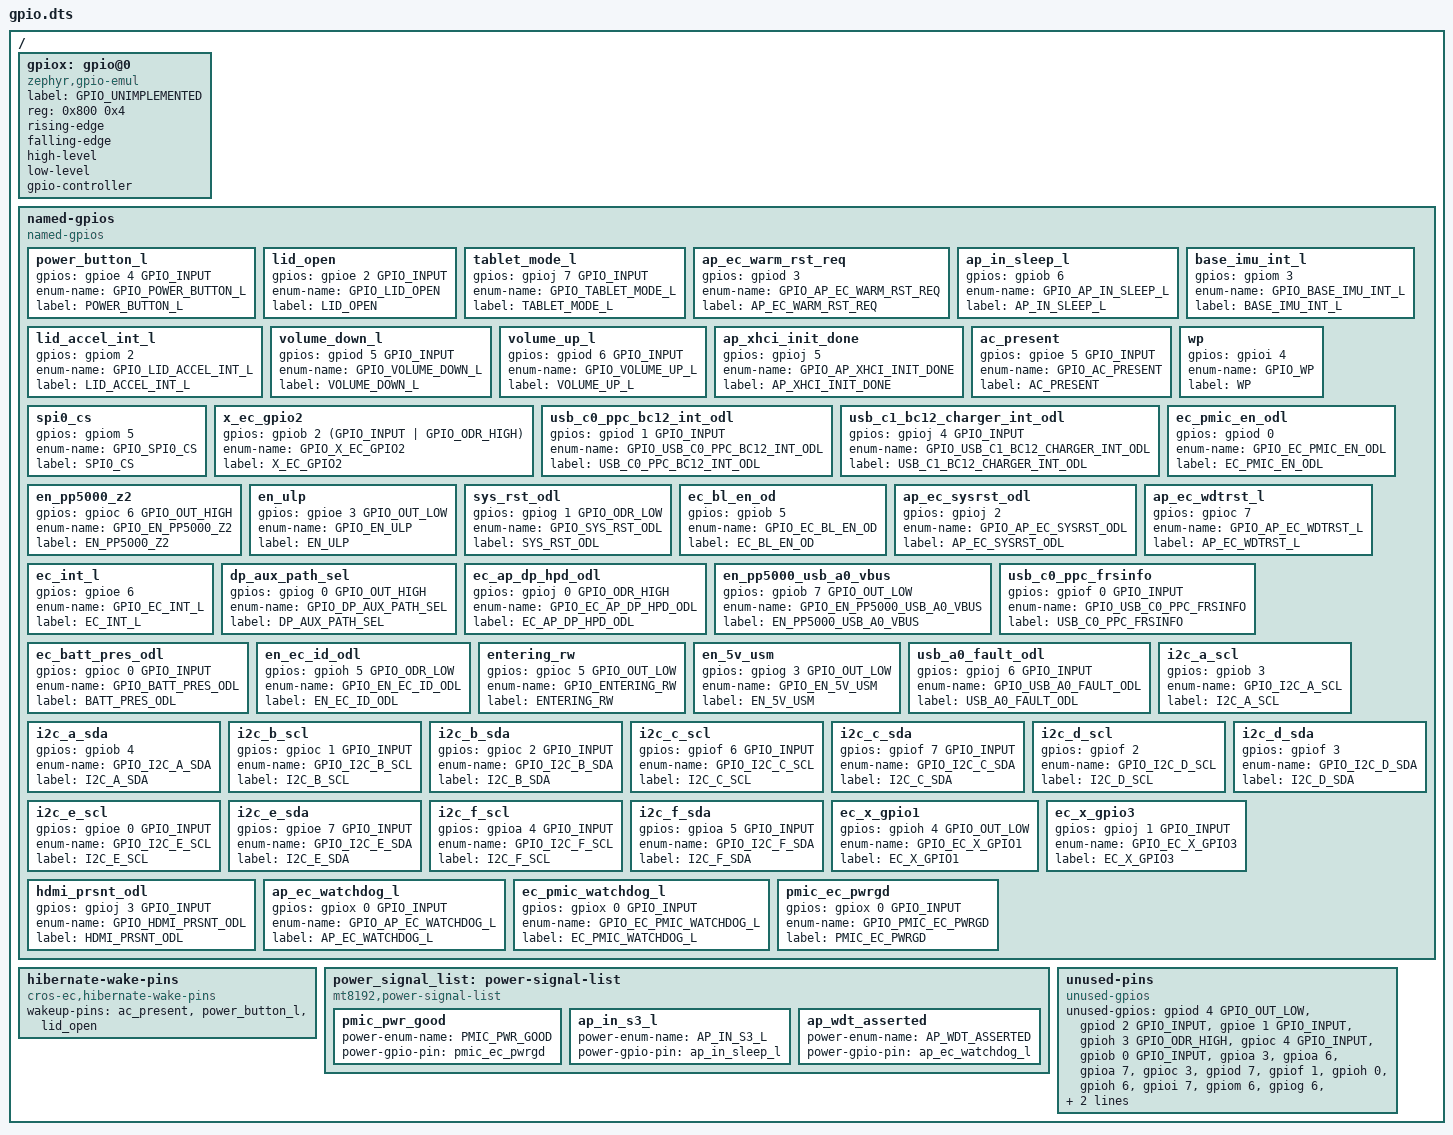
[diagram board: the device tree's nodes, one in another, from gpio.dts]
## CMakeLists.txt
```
# Copyright 2021 The Chromium OS Authors. All rights reserved.
# Use of this source code is governed by a BSD-style license that can be
# found in the LICENSE file.

cmake_minimum_required(VERSION 3.13.1)
add_compile_definitions(BOARD_KRABBY)

find_package(Zephyr REQUIRED HINTS $ENV{ZEPHYR_BASE})
project(krabby)

zephyr_library_include_directories(include)

set(PLATFORM_EC_BASEBOARD "${PLATFORM_EC}/baseboard/corsola" CACHE PATH
    "Path to the platform/ec baseboard directory")
set(PLATFORM_EC_BOARD "${PLATFORM_EC}/board/krabby" CACHE PATH
  "Path to the platform/ec board directory")

# Include selected EC source from the baseboard
zephyr_library_sources(
  "${PLATFORM_EC_BASEBOARD}/board_chipset.c"
  "${PLATFORM_EC_BASEBOARD}/board_id.c"
  "${PLATFORM_EC_BASEBOARD}/hibernate.c"
  "${PLATFORM_EC_BASEBOARD}/regulator.c"
  "${PLATFORM_EC_BASEBOARD}/usbc_config.c"
  "${PLATFORM_EC_BASEBOARD}/usb_pd_policy.c")

# Include selected EC source from the board
zephyr_library_sources(
  "${PLATFORM_EC_BOARD}/hooks.c"
  "${PLATFORM_EC_BOARD}/led.c")

zephyr_library_sources_ifdef(CONFIG_PLATFORM_EC_I2C
  "src/i2c.c")
```

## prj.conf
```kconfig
# Copyright 2021 The Chromium OS Authors. All rights reserved.
# Use of this source code is governed by a BSD-style license that can be
# found in the LICENSE file.

CONFIG_CROS_EC=y
CONFIG_PLATFORM_EC=y
CONFIG_SHIMMED_TASKS=y

# Bring up options
CONFIG_KERNEL_SHELL=y
CONFIG_PLATFORM_EC_SYSTEM_UNLOCKED=y
CONFIG_GPIO_EMUL=y

# Battery
CONFIG_PLATFORM_EC_BATTERY=y
CONFIG_PLATFORM_EC_BATTERY_CUT_OFF=y
CONFIG_PLATFORM_EC_BATTERY_FUEL_GAUGE=y
CONFIG_PLATFORM_EC_BATTERY_PRESENT_GPIO=y
CONFIG_PLATFORM_EC_BATTERY_SMART=y
CONFIG_PLATFORM_EC_BATT_FULL_CHIPSET_OFF_INPUT_LIMIT_MV=9000
CONFIG_PLATFORM_EC_I2C_PASSTHRU_RESTRICTED=y
CONFIG_PLATFORM_EC_I2C_VIRTUAL_BATTERY=y

# Charger
CONFIG_PLATFORM_EC_CHARGE_MANAGER=y
CONFIG_PLATFORM_EC_CHARGE_RAMP_HW=y
CONFIG_PLATFORM_EC_CHARGER_DISCHARGE_ON_AC=y
CONFIG_PLATFORM_EC_CHARGER_DISCHARGE_ON_AC_CHARGER=y
CONFIG_PLATFORM_EC_CHARGER_ISL9238C=y
CONFIG_PLATFORM_EC_CHARGER_MAINTAIN_VBAT=y
CONFIG_PLATFORM_EC_CHARGER_OTG=y
CONFIG_PLATFORM_EC_CHARGER_PSYS=y
CONFIG_PLATFORM_EC_CHARGER_PSYS_READ=y
# BOARD_RS2
CONFIG_PLATFORM_EC_CHARGER_SENSE_RESISTOR=10
# BOARD_RS1
CONFIG_PLATFORM_EC_CHARGER_SENSE_RESISTOR_AC=20

# Host Commands
CONFIG_PLATFORM_EC_HOSTCMD=y
CONFIG_PLATFORM_EC_CONSOLE_CMD_ACCELS=y
CONFIG_PLATFORM_EC_CONSOLE_CMD_ACCEL_INFO=y
CONFIG_PLATFORM_EC_CONSOLE_CMD_CHARGER_ADC_AMON_BMON=y
CONFIG_PLATFORM_EC_CONSOLE_CMD_SYSINFO=y
CONFIG_PLATFORM_EC_HOSTCMD_REGULATOR=y
CONFIG_PLATFORM_EC_HOST_COMMAND_STATUS=y

# LED
CONFIG_PLATFORM_EC_LED_COMMON=y
CONFIG_PLATFORM_EC_LED_ONOFF_STATES=y
CONFIG_PLATFORM_EC_LED_ONOFF_STATES_BAT_LOW=10

# MKBP event mask
CONFIG_PLATFORM_EC_MKBP_EVENT_WAKEUP_MASK=y
CONFIG_PLATFORM_EC_MKBP_HOST_EVENT_WAKEUP_MASK=y
CONFIG_PLATFORM_EC_MKBP_USE_GPIO=y

# Keyboard
CONFIG_PLATFORM_EC_KEYBOARD=y
CONFIG_PLATFORM_EC_KEYBOARD_PROTOCOL_MKBP=y
CONFIG_PLATFORM_EC_KEYBOARD_COL2_INVERTED=y
CONFIG_PLATFORM_EC_VOLUME_BUTTONS=y
CONFIG_PLATFORM_EC_CMD_BUTTON=y

# Sensors
CONFIG_PLATFORM_EC_MOTIONSENSE=y
CONFIG_PLATFORM_EC_ACCEL_FIFO=y
CONFIG_PLATFORM_EC_ACCEL_INTERRUPTS=y
CONFIG_PLATFORM_EC_GMR_TABLET_MODE=y
CONFIG_PLATFORM_EC_LID_ANGLE=y
CONFIG_PLATFORM_EC_LID_ANGLE_UPDATE=y
CONFIG_PLATFORM_EC_SENSOR_TIGHT_TIMESTAMPS=y
CONFIG_PLATFORM_EC_SWITCH=y
CONFIG_PLATFORM_EC_TABLET_MODE=y
CONFIG_PLATFORM_EC_TABLET_MODE_SWITCH=y

# Sensor Drivers
CONFIG_PLATFORM_EC_ACCEL_LIS2DW12=y
CONFIG_PLATFORM_EC_ACCEL_LIS2DW12_AS_BASE=y
CONFIG_PLATFORM_EC_ACCELGYRO_BMI160=y
CONFIG_PLATFORM_EC_ACCELGYRO_BMI_COMM_I2C=y

# USB-A
CONFIG_PLATFORM_EC_USB_A_PORT_COUNT=1

# USB-C
CONFIG_PLATFORM_EC_BC12_DETECT_PI3USB9201=y
CONFIG_PLATFORM_EC_BC12_DETECT_MT6360=y
CONFIG_PLATFORM_EC_BC12_SINGLE_DRIVER=n
CONFIG_PLATFORM_EC_SMBUS_PEC=y
CONFIG_PLATFORM_EC_USBC_PPC_DEDICATED_INT=y
CONFIG_PLATFORM_EC_USBC_PPC_SYV682C=y
CONFIG_PLATFORM_EC_USBC_PPC_SYV682X=y
CONFIG_PLATFORM_EC_USB_MUX_IT5205=y
CONFIG_PLATFORM_EC_USB_MUX_PS8743=y
CONFIG_PLATFORM_EC_USB_MUX_VIRTUAL=y
CONFIG_PLATFORM_EC_USB_PD_DISCHARGE_PPC=y
CONFIG_PLATFORM_EC_USB_PD_DP_HPD_GPIO=y
CONFIG_PLATFORM_EC_USB_PD_DP_HPD_GPIO_CUSTOM=y
CONFIG_PLATFORM_EC_USB_PD_FRS=y
CONFIG_PLATFORM_EC_USB_PD_FRS_PPC=y
CONFIG_PLATFORM_EC_USB_PD_ITE_ACTIVE_PORT_COUNT=2
CONFIG_PLATFORM_EC_USB_PD_LOGGING=y
CONFIG_PLATFORM_EC_USB_PD_TCPM_DRIVER_IT8XXX2=y
CONFIG_PLATFORM_EC_USB_PD_TCPC_RUNTIME_CONFIG=n
CONFIG_PLATFORM_EC_USB_MUX_RUNTIME_CONFIG=n
CONFIG_PLATFORM_EC_USB_PD_TCPM_ITE_ON_CHIP=y
CONFIG_PLATFORM_EC_USB_PD_TCPM_TCPCI=y
CONFIG_PLATFORM_EC_USB_PD_VBUS_DETECT_PPC=y
CONFIG_PLATFORM_EC_USB_PD_VBUS_MEASURE_ADC_EACH_PORT=y
CONFIG_PLATFORM_EC_USB_PORT_POWER_DUMB_CUSTOM_HOOK=y
CONFIG_PLATFORM_EC_USB_PD_DUAL_ROLE_AUTO_TOGGLE=n
CONFIG_PLATFORM_EC_USB_PD_USB32_DRD=n
CONFIG_PLATFORM_EC_USB_PD_USB4=n
CONFIG_PLATFORM_EC_USB_PD_TBT_COMPAT_MODE=n

# TODO: Assign a PID for Corsola
# USB ID
# This is allocated for Corsola
# http://google3/hardware/standards/usb/
# TODO(b/183608112): Move to device tree
CONFIG_PLATFORM_EC_USB_PID=0x5566

# VBoot without EFS2
CONFIG_PLATFORM_EC_VBOOT_EFS2=n
CONFIG_PLATFORM_EC_VBOOT_HASH=y

# TODO(b/180980668): bring these features up
CONFIG_LTO=n
CONFIG_PLATFORM_EC_BACKLIGHT_LID=n
```

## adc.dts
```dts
/* Copyright 2021 The Chromium OS Authors. All rights reserved.
 * Use of this source code is governed by a BSD-style license that can be
 * found in the LICENSE file.
 */

/ {
	named-adc-channels {
		compatible = "named-adc-channels";

		adc_vbus_c0 {
			label = "ADC_VBUS_C0";
			enum-name = "ADC_VBUS_C0";
			channel = <0>;
			mul = <10>;
		};
		adc_board_id0 {
			label = "ADC_BOARD_ID_0";
			enum-name = "ADC_BOARD_ID_0";
			channel = <1>;
		};
		adc_board_id1 {
			label = "ADC_BOARD_ID_1";
			enum-name = "ADC_BOARD_ID_1";
			channel = <2>;
		};
		adc_charger_amon_r {
			label = "ADC_AMON_BMON";
			enum-name = "ADC_AMON_BMON";
			channel = <3>;
			mul = <1000>;
			div = <18>;
		};
		adc_vbus_c1 {
			label = "ADC_VBUS_C1";
			enum-name = "ADC_VBUS_C1";
			channel = <5>;
			mul = <10>;
		};
		adc_charger_pmon {
			label = "ADC_PMON";
			enum-name = "ADC_PMON";
			channel = <6>;
		};
		adc-psys {
			label = "ADC_PSYS";
			enum-name = "ADC_PSYS";
			channel = <6>;
		};
	};
};

&adc0 {
	status = "okay";
};
```

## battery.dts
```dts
/* Copyright 2021 The Chromium OS Authors. All rights reserved.
 * Use of this source code is governed by a BSD-style license that can be
 * found in the LICENSE file.
 */

/ {
	batteries {
		default_battery: c235 {
			compatible = "as3gwrc3ka,c235-41";
		};
	};
};
```

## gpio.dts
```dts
/* Copyright 2021 The Chromium OS Authors. All rights reserved.
 * Use of this source code is governed by a BSD-style license that can be
 * found in the LICENSE file.
 */

/ {
	gpiox: gpio@0 {
		status = "okay";
		compatible = "zephyr,gpio-emul";
		label = "GPIO_UNIMPLEMENTED";
		reg = <0x800 0x4>;
		rising-edge;
		falling-edge;
		high-level;
		low-level;
		gpio-controller;
		#gpio-cells = <2>;
	};

	named-gpios {
		compatible = "named-gpios";

		power_button_l: power_button_l {
			gpios = <&gpioe 4 GPIO_INPUT>;
			enum-name = "GPIO_POWER_BUTTON_L";
			label = "POWER_BUTTON_L";
		};
		lid_open: lid_open {
			gpios = <&gpioe 2 GPIO_INPUT>;
			enum-name = "GPIO_LID_OPEN";
			label = "LID_OPEN";
		};
		tablet_mode_l: tablet_mode_l {
			gpios = <&gpioj 7 GPIO_INPUT>;
			enum-name = "GPIO_TABLET_MODE_L";
			label = "TABLET_MODE_L";
		};
		ap_ec_warm_rst_req: ap_ec_warm_rst_req {
			gpios = <&gpiod 3 (GPIO_INPUT | GPIO_VOLTAGE_1P8)>;
			enum-name = "GPIO_AP_EC_WARM_RST_REQ";
			label = "AP_EC_WARM_RST_REQ";
		};
		ap_in_sleep_l: ap_in_sleep_l {
			gpios = <&gpiob 6 (GPIO_INPUT | GPIO_VOLTAGE_1P8)>;
			enum-name = "GPIO_AP_IN_SLEEP_L";
			label = "AP_IN_SLEEP_L";
		};
		base_imu_int_l: base_imu_int_l {
			gpios = <&gpiom 3 (GPIO_INPUT | GPIO_VOLTAGE_1P8)>;
			enum-name = "GPIO_BASE_IMU_INT_L";
			label = "BASE_IMU_INT_L";
		};
		lid_accel_int_l: lid_accel_int_l {
			gpios = <&gpiom 2 (GPIO_INPUT | GPIO_VOLTAGE_1P8)>;
			enum-name = "GPIO_LID_ACCEL_INT_L";
			label = "LID_ACCEL_INT_L";
		};
		volume_down_l: volume_down_l {
			gpios = <&gpiod 5 GPIO_INPUT>;
			enum-name = "GPIO_VOLUME_DOWN_L";
			label = "VOLUME_DOWN_L";
		};
		volume_up_l: volume_up_l {
			gpios = <&gpiod 6 GPIO_INPUT>;
			enum-name = "GPIO_VOLUME_UP_L";
			label = "VOLUME_UP_L";
		};
		ap_xhci_init_done: ap_xhci_init_done {
			gpios = <&gpioj 5 (GPIO_INPUT | GPIO_VOLTAGE_1P8)>;
			enum-name = "GPIO_AP_XHCI_INIT_DONE";
			label = "AP_XHCI_INIT_DONE";
		};
		ac_present: ac_present {
			gpios = <&gpioe 5 GPIO_INPUT>;
			enum-name = "GPIO_AC_PRESENT";
			label = "AC_PRESENT";
		};
		wp: wp {
			gpios = <&gpioi 4 (GPIO_INPUT | GPIO_VOLTAGE_1P8)>;
			enum-name = "GPIO_WP";
			label = "WP";
		};
		spi0_cs: spi0_cs {
			gpios = <&gpiom 5 (GPIO_INPUT | GPIO_VOLTAGE_1P8)>;
			enum-name = "GPIO_SPI0_CS";
			label = "SPI0_CS";
		};
		x_ec_gpio2: x_ec_gpio2 {
			gpios = <&gpiob 2 (GPIO_INPUT | GPIO_ODR_HIGH)>;
			enum-name = "GPIO_X_EC_GPIO2";
			label = "X_EC_GPIO2";
		};
		usb_c0_ppc_bc12_int_odl: usb_c0_ppc_bc12_int_odl {
			gpios = <&gpiod 1 GPIO_INPUT>;
			enum-name = "GPIO_USB_C0_PPC_BC12_INT_ODL";
			label = "USB_C0_PPC_BC12_INT_ODL";
		};
		usb_c1_bc12_charger_int_odl: usb_c1_bc12_charger_int_odl {
			gpios = <&gpioj 4 GPIO_INPUT>;
			enum-name = "GPIO_USB_C1_BC12_CHARGER_INT_ODL";
			label = "USB_C1_BC12_CHARGER_INT_ODL";
		};
		ec_pmic_en_odl: ec_pmic_en_odl {
			gpios = <&gpiod 0 (GPIO_ODR_HIGH | GPIO_VOLTAGE_1P8)>;
			enum-name = "GPIO_EC_PMIC_EN_ODL";
			label = "EC_PMIC_EN_ODL";
		};
		en_pp5000_z2: en_pp5000_z2 {
			gpios = <&gpioc 6 GPIO_OUT_HIGH>;
			enum-name = "GPIO_EN_PP5000_Z2";
			label = "EN_PP5000_Z2";
		};
		en_ulp: en_ulp {
			gpios = <&gpioe 3 GPIO_OUT_LOW>;
			enum-name = "GPIO_EN_ULP";
			label = "EN_ULP";
		};
		sys_rst_odl: sys_rst_odl {
			gpios = <&gpiog 1 GPIO_ODR_LOW>;
			enum-name = "GPIO_SYS_RST_ODL";
			label = "SYS_RST_ODL";
		};
		ec_bl_en_od: ec_bl_en_od {
			gpios = <&gpiob 5 (GPIO_ODR_LOW | GPIO_VOLTAGE_1P8)>;
			enum-name = "GPIO_EC_BL_EN_OD";
			label = "EC_BL_EN_OD";
		};
		ap_ec_sysrst_odl: ap_ec_sysrst_odl {
			gpios = <&gpioj 2 (GPIO_INPUT | GPIO_VOLTAGE_1P8)>;
			enum-name = "GPIO_AP_EC_SYSRST_ODL";
			label = "AP_EC_SYSRST_ODL";
		};
		ap_ec_wdtrst_l: ap_ec_wdtrst_l {
			gpios = <&gpioc 7 (GPIO_INPUT | GPIO_VOLTAGE_1P8)>;
			enum-name = "GPIO_AP_EC_WDTRST_L";
			label = "AP_EC_WDTRST_L";
		};
		ec_int_l: ec_int_l {
			gpios = <&gpioe 6 (GPIO_ODR_HIGH | GPIO_VOLTAGE_1P8)>;
			enum-name = "GPIO_EC_INT_L";
			label = "EC_INT_L";
		};
		dp_aux_path_sel: dp_aux_path_sel {
			gpios = <&gpiog 0 GPIO_OUT_HIGH>;
			enum-name = "GPIO_DP_AUX_PATH_SEL";
			label = "DP_AUX_PATH_SEL";
		};
		ec_ap_dp_hpd_odl: ec_ap_dp_hpd_odl {
			gpios = <&gpioj 0 GPIO_ODR_HIGH>;
			enum-name = "GPIO_EC_AP_DP_HPD_ODL";
			label = "EC_AP_DP_HPD_ODL";
		};
		en_pp5000_usb_a0_vbus: en_pp5000_usb_a0_vbus {
			gpios = <&gpiob 7 GPIO_OUT_LOW>;
			enum-name = "GPIO_EN_PP5000_USB_A0_VBUS";
			label = "EN_PP5000_USB_A0_VBUS";
		};
		usb_c0_ppc_frsinfo: usb_c0_ppc_frsinfo {
			gpios = <&gpiof 0 GPIO_INPUT>;
			enum-name = "GPIO_USB_C0_PPC_FRSINFO";
			label = "USB_C0_PPC_FRSINFO";
		};
		ec_batt_pres_odl: ec_batt_pres_odl {
			gpios = <&gpioc 0 GPIO_INPUT>;
			enum-name = "GPIO_BATT_PRES_ODL";
			label = "BATT_PRES_ODL";
		};
		en_ec_id_odl: en_ec_id_odl {
			gpios = <&gpioh 5 GPIO_ODR_LOW>;
			enum-name = "GPIO_EN_EC_ID_ODL";
			label = "EN_EC_ID_ODL";
		};
		entering_rw: entering_rw {
			gpios = <&gpioc 5 GPIO_OUT_LOW>;
			enum-name = "GPIO_ENTERING_RW";
			label = "ENTERING_RW";
		};
		en_5v_usm: en_5v_usm {
			gpios = <&gpiog 3 GPIO_OUT_LOW>;
			enum-name = "GPIO_EN_5V_USM";
			label = "EN_5V_USM";
		};
		usb_a0_fault_odl: usb_a0_fault_odl {
			gpios = <&gpioj 6 GPIO_INPUT>;
			enum-name = "GPIO_USB_A0_FAULT_ODL";
			label = "USB_A0_FAULT_ODL";
		};
		i2c_a_scl: i2c_a_scl {
			gpios = <&gpiob 3 (GPIO_INPUT | GPIO_VOLTAGE_1P8)>;
			enum-name = "GPIO_I2C_A_SCL";
			label = "I2C_A_SCL";
		};
		i2c_a_sda: i2c_a_sda {
			gpios = <&gpiob 4 (GPIO_INPUT | GPIO_VOLTAGE_1P8)>;
			enum-name = "GPIO_I2C_A_SDA";
			label = "I2C_A_SDA";
		};
		i2c_b_scl: i2c_b_scl {
			gpios = <&gpioc 1 GPIO_INPUT>;
			enum-name = "GPIO_I2C_B_SCL";
			label = "I2C_B_SCL";
		};
		i2c_b_sda: i2c_b_sda {
			gpios = <&gpioc 2 GPIO_INPUT>;
			enum-name = "GPIO_I2C_B_SDA";
			label = "I2C_B_SDA";
		};
		i2c_c_scl: i2c_c_scl {
			gpios = <&gpiof 6 GPIO_INPUT>;
			enum-name = "GPIO_I2C_C_SCL";
			label = "I2C_C_SCL";
		};
		i2c_c_sda: i2c_c_sda {
			gpios = <&gpiof 7 GPIO_INPUT>;
			enum-name = "GPIO_I2C_C_SDA";
			label = "I2C_C_SDA";
		};
		i2c_d_scl: i2c_d_scl {
			gpios = <&gpiof 2 (GPIO_INPUT | GPIO_VOLTAGE_1P8)>;
			enum-name = "GPIO_I2C_D_SCL";
			label = "I2C_D_SCL";
		};
		i2c_d_sda: i2c_d_sda {
			gpios = <&gpiof 3 (GPIO_INPUT | GPIO_VOLTAGE_1P8)>;
			enum-name = "GPIO_I2C_D_SDA";
			label = "I2C_D_SDA";
		};
		i2c_e_scl: i2c_e_scl {
			gpios = <&gpioe 0 GPIO_INPUT>;
			enum-name = "GPIO_I2C_E_SCL";
			label = "I2C_E_SCL";
		};
		i2c_e_sda: i2c_e_sda {
			gpios = <&gpioe 7 GPIO_INPUT>;
			enum-name = "GPIO_I2C_E_SDA";
			label = "I2C_E_SDA";
		};
		i2c_f_scl: i2c_f_scl {
			gpios = <&gpioa 4 GPIO_INPUT>;
			enum-name = "GPIO_I2C_F_SCL";
			label = "I2C_F_SCL";
		};
		i2c_f_sda: i2c_f_sda {
			gpios = <&gpioa 5 GPIO_INPUT>;
			enum-name = "GPIO_I2C_F_SDA";
			label = "I2C_F_SDA";
		};
		ec_x_gpio1: ec_x_gpio1 {
			gpios = <&gpioh 4 GPIO_OUT_LOW>;
			enum-name = "GPIO_EC_X_GPIO1";
			label = "EC_X_GPIO1";
		};
		ec_x_gpio3: ec_x_gpio3 {
			gpios = <&gpioj 1 GPIO_INPUT>;
			enum-name = "GPIO_EC_X_GPIO3";
			label = "EC_X_GPIO3";
		};
		hdmi_prsnt_odl: hdmi_prsnt_odl {
			gpios = <&gpioj 3 GPIO_INPUT>;
			enum-name = "GPIO_HDMI_PRSNT_ODL";
			label = "HDMI_PRSNT_ODL";
		};

		/* pins used in power/mt8192, to be removed */
		ap_ec_watchdog_l: ap_ec_watchdog_l {
			gpios = <&gpiox 0 GPIO_INPUT>;
			enum-name = "GPIO_AP_EC_WATCHDOG_L";
			label = "AP_EC_WATCHDOG_L";
		};
		ec_pmic_watchdog_l: ec_pmic_watchdog_l {
			gpios = <&gpiox 0 GPIO_INPUT>;
			enum-name = "GPIO_EC_PMIC_WATCHDOG_L";
			label = "EC_PMIC_WATCHDOG_L";
		};
		pmic_ec_pwrgd: pmic_ec_pwrgd {
			gpios = <&gpiox 0 GPIO_INPUT>;
			enum-name = "GPIO_PMIC_EC_PWRGD";
			label = "PMIC_EC_PWRGD";
		};
	};

	hibernate-wake-pins {
		compatible = "cros-ec,hibernate-wake-pins";
		wakeup-pins = <&ac_present
			       &power_button_l
			       &lid_open>;
	};

	power_signal_list: power-signal-list {
		compatible = "mt8192,power-signal-list";
		pmic_pwr_good {
			power-enum-name = "PMIC_PWR_GOOD";
			power-gpio-pin = <&pmic_ec_pwrgd>;
		};
		ap_in_s3_l {
			power-enum-name = "AP_IN_S3_L";
			power-gpio-pin = <&ap_in_sleep_l>;
		};
		ap_wdt_asserted {
			power-enum-name = "AP_WDT_ASSERTED";
			power-gpio-pin = <&ap_ec_watchdog_l>;
		};
	};

	unused-pins {
		compatible = "unused-gpios";

		unused-gpios =
			/* packet_mode_en */
			<&gpiod 4 GPIO_OUT_LOW>,
			/* pg_pp5000_z2_od */
			<&gpiod 2 GPIO_INPUT>,
			/* pg_mt6315_proc_b_odl */
			<&gpioe 1 GPIO_INPUT>,
			/* ec_pen_chg_dis_odl */
			<&gpioh 3 GPIO_ODR_HIGH>,
			/* ccd_mode_odl */
			<&gpioc 4 GPIO_INPUT>,
			/* uart1_rx */
			<&gpiob 0 GPIO_INPUT>,
			/* unnamed nc pins */
			<&gpioa 3 (GPIO_INPUT | GPIO_PULL_DOWN)>,
			<&gpioa 6 (GPIO_INPUT | GPIO_PULL_DOWN)>,
			<&gpioa 7 (GPIO_INPUT | GPIO_PULL_DOWN)>,
			<&gpioc 3 (GPIO_INPUT | GPIO_PULL_DOWN)>,
			<&gpiod 7 (GPIO_INPUT | GPIO_PULL_DOWN)>,
			<&gpiof 1 (GPIO_INPUT | GPIO_PULL_DOWN)>,
			<&gpioh 0 (GPIO_INPUT | GPIO_PULL_DOWN)>,
			<&gpioh 6 (GPIO_INPUT | GPIO_PULL_DOWN)>,
			<&gpioi 7 (GPIO_INPUT | GPIO_PULL_DOWN)>,
			<&gpiom 6 (GPIO_INPUT | GPIO_PULL_DOWN)>,
			/* spi_clk_gpg6 */
			<&gpiog 6 (GPIO_INPUT | GPIO_PULL_UP)>,
			/* spi_mosi_gpg4 */
			<&gpiog 4 GPIO_OUT_LOW>,
			/* spi_miso_gpg5 */
			<&gpiog 5 GPIO_OUT_LOW>,
			/* spi_cs_gpg7 */
			<&gpiog 7 GPIO_OUT_LOW>;
	};
};
```

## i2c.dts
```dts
/* Copyright 2021 The Chromium OS Authors. All rights reserved.
 * Use of this source code is governed by a BSD-style license that can be
 * found in the LICENSE file.
 */

/ {
	named-i2c-ports {
		compatible = "named-i2c-ports";

		power {
			i2c-port = <&i2c0>;
			enum-name = "I2C_PORT_POWER";
			label = "POWER";
		};
		battery {
			i2c-port = <&i2c0>;
			remote-port = <0>;
			enum-name = "I2C_PORT_BATTERY";
			label = "BATTERY";
		};
		virtual-battery {
			i2c-port = <&i2c0>;
			enum-name = "I2C_PORT_VIRTUAL_BATTERY";
			label = "VIRTUAL_BATTERY";
		};
		eeprom {
			i2c-port = <&i2c0>;
			enum-name = "I2C_PORT_EEPROM";
			label = "EEPROM";
		};
		charger {
			i2c-port = <&i2c0>;
			enum-name = "I2C_PORT_CHARGER";
			label = "CHARGER";
		};
		i2c_sensor: sensor {
			i2c-port = <&i2c1>;
			enum-name = "I2C_PORT_SENSOR";
			label = "SENSOR";
		};
		i2c-accel {
			i2c-port = <&i2c1>;
			enum-name = "I2C_PORT_ACCEL";
			label = "ACCEL";
		};
		ppc0 {
			i2c-port = <&i2c2>;
			enum-name = "I2C_PORT_PPC0";
			label = "PPC0";
		};
		ppc1 {
			i2c-port = <&i2c4>;
			enum-name = "I2C_PORT_PPC1";
			label = "PPC1";
		};
		usb-c0 {
			i2c-port = <&i2c2>;
			enum-name = "I2C_PORT_USB_C0";
			label = "USB_C0";
		};
		usb-c1 {
			i2c-port = <&i2c4>;
			enum-name = "I2C_PORT_USB_C1";
			label = "USB_C1";
		};
		usb-mux0 {
			i2c-port = <&i2c2>;
			enum-name = "I2C_PORT_USB_MUX0";
			label = "USB_MUX0";
		};
		usb-mux1 {
			i2c-port = <&i2c4>;
			enum-name = "I2C_PORT_USB_MUX1";
			label = "USB_MUX1";
		};
	};

};

&i2c0 {
	/* EC_I2C_PWR_CBI */
	status = "okay";
	clock-frequency = <I2C_BITRATE_STANDARD>;
};

&i2c1 {
	/* EC_I2C_SENSOR */
	status = "okay";
	clock-frequency = <I2C_BITRATE_FAST>;
};

&i2c2 {
	/* EC_I2C_USB_C0 */
	status = "okay";
	clock-frequency = <I2C_BITRATE_FAST>;
};

&i2c4 {
	/* EC_I2C_USB_C1 */
	status = "okay";
	clock-frequency = <I2C_BITRATE_FAST>;
};
```

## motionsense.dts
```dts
/* Copyright 2020 The Chromium OS Authors. All rights reserved.
 * Use of this source code is governed by a BSD-style license that can be
 * found in the LICENSE file.
 */

#include <dt-bindings/motionsense/utils.h>


/ {
	aliases {
		/*
		 * motion sense's <>_INT_EVENT is handled
		 * by alias. Using the alias, each driver creates
		 * its own <>_INT_EVENT.
		 */
		bmi160-int = &base_accel;
		lis2dw12-int = &lid_accel;
	};

	/*
	 * Declare mutexes used by sensor drivers.
	 * A mutex node is used to create an instance of mutex_t.
	 * A mutex node is referenced by a sensor node if the
	 * corresponding sensor driver needs to use the
	 * instance of the mutex.
	 */
	motionsense-mutex {
		compatible = "cros-ec,motionsense-mutex";
		lid_mutex: lid-mutex {
			label = "LID_MUTEX";
		};

		mutex_bmi160: bmi160-mutex {
			label = "BMI160_MUTEX";
		};
	};

	/* Rotation matrix used by drivers. */
	motionsense-rotation-ref {
		compatible = "cros-ec,motionsense-rotation-ref";
		lid_rot_ref: lid-rotation-ref {
			mat33 = <(-1) 0 0
				 0 (-1) 0
				 0 0 1>;
		};

		base_rot_ref: base-rotation-ref {
			mat33 = <1 0 0
				 0 (-1) 0
				 0 0 (-1)>;
		};
	};

	/*
	 * Driver specific data. A driver-specific data can be shared with
	 * different motion sensors while they are using the same driver.
	 *
	 * If a node's compatible starts with "cros-ec,accelgyro-", it is for
	 * a common structure defined in accelgyro.h.
	 * e.g) compatible = "cros-ec,accelgyro-als-drv-data" is for
	 * "struct als_drv_data_t" in accelgyro.h
	 */
	motionsense-sensor-data {
		bmi160_data: bmi160-drv-data {
			compatible = "cros-ec,drvdata-bmi160";
			status = "okay";
		};

		lis2dw12_data: lis2dw12-drv-data {
			compatible = "cros-ec,drvdata-lis2dw12";
			status = "okay";
		};
	};

	/*
	 * List of motion sensors that creates motion_sensors array.
	 * The label "lid_accel" and "base_accel" are used to indicate
	 * motion sensor IDs for lid angle calculation.
	 */
	motionsense-sensor {
		lid_accel: lid-accel {
			compatible = "cros-ec,lis2dw12";
			status = "okay";

			label = "Lid Accel";
			active-mask = "SENSOR_ACTIVE_S0_S3";
			location = "MOTIONSENSE_LOC_LID";
			mutex = <&lid_mutex>;
			port = <&i2c_sensor>;
			rot-standard-ref = <&lid_rot_ref>;
			default-range = <2>;
			drv-data = <&lis2dw12_data>;
			configs {
				compatible =
					"cros-ec,motionsense-sensor-config";
				ec-s0 {
					label = "SENSOR_CONFIG_EC_S0";
					odr = <(10000 | ROUND_UP_FLAG)>;
				};
				ec-s3 {
					label = "SENSOR_CONFIG_EC_S3";
					odr = <(10000 | ROUND_UP_FLAG)>;
				};
			};
		};

		base_accel: base-accel {
			compatible = "cros-ec,bmi160-accel";
			status = "okay";

			label = "Base Accel";
			active-mask = "SENSOR_ACTIVE_S0_S3";
			location = "MOTIONSENSE_LOC_BASE";
			mutex = <&mutex_bmi160>;
			port = <&i2c_sensor>;
			rot-standard-ref = <&base_rot_ref>;
			drv-data = <&bmi160_data>;
			configs {
				compatible =
					"cros-ec,motionsense-sensor-config";
				ec-s0 {
					label = "SENSOR_CONFIG_EC_S0";
					odr = <(10000 | ROUND_UP_FLAG)>;
				};
				ec-s3 {
					label = "SENSOR_CONFIG_EC_S3";
					odr = <(10000 | ROUND_UP_FLAG)>;
				};
			};
		};

		base-gyro {
			compatible = "cros-ec,bmi160-gyro";
			status = "okay";

			label = "Base Gyro";
			active-mask = "SENSOR_ACTIVE_S0_S3";
			location = "MOTIONSENSE_LOC_BASE";
			mutex = <&mutex_bmi160>;
			port = <&i2c_sensor>;
			rot-standard-ref = <&base_rot_ref>;
			drv-data = <&bmi160_data>;
		};
	};

	motionsense-sensor-info {
		compatible = "cros-ec,motionsense-sensor-info";

		/*
		 * list of GPIO interrupts that have to
		 * be enabled at initial stage
		 */
		sensor-irqs = <&base_imu_int_l>;
		/* list of sensors in force mode */
		accel-force-mode-sensors = <&lid_accel>;
	};
};
```

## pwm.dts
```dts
/* Copyright 2021 The Chromium OS Authors. All rights reserved.
 * Use of this source code is governed by a BSD-style license that can be
 * found in the LICENSE file.
 */

/ {
	named-pwms {
		compatible = "named-pwms";
		/* NOTE: &pwm number needs same with channel number */
		led1: led1 {
			#pwm-cells = <0>;
			pwms = <&pwm0 PWM_CHANNEL_0 PWM_POLARITY_INVERTED>;
			label = "LED1";
			/*
			 * If we need pwm output in ITE chip power saving
			 * mode, then we should set frequency <=324Hz.
			 */
			frequency = <324>;
		};
		led2: led2 {
			#pwm-cells = <0>;
			pwms = <&pwm1 PWM_CHANNEL_1 PWM_POLARITY_INVERTED>;
			label = "LED2";
			frequency = <324>;
		};
		led3: led3 {
			#pwm-cells = <0>;
			pwms = <&pwm2 PWM_CHANNEL_2 PWM_POLARITY_INVERTED>;
			label = "LED3";
			frequency = <324>;
		};
	};
};

/* LED1 */
&pwm0 {
	status = "okay";
	prescaler-cx = <PWM_PRESCALER_C4>;
};

/* LED2 */
&pwm1 {
	status = "okay";
	prescaler-cx = <PWM_PRESCALER_C4>;
};

/* LED3 */
&pwm2 {
	status = "okay";
	prescaler-cx = <PWM_PRESCALER_C4>;
};
```

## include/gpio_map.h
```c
/* Copyright 2021 The Chromium OS Authors. All rights reserved.
 * Use of this source code is governed by a BSD-style license that can be
 * found in the LICENSE file.
 */

#ifndef __ZEPHYR_GPIO_MAP_H
#define __ZEPHYR_GPIO_MAP_H

#include <devicetree.h>
#include <gpio_signal.h>

/*
 * TODO(b:188674805) create a driver to pull this information from DeviceTree
 */
#include "power/mt8192.h"

#define GPIO_ENTERING_RW		GPIO_UNIMPLEMENTED
#define GPIO_WP_L			GPIO_UNIMPLEMENTED

#ifdef CONFIG_PLATFORM_EC_GMR_TABLET_MODE
#define GMR_TABLET_MODE_GPIO_L GPIO_TABLET_MODE_L
#endif

/* TODO: remove after icm426xx driver added */
static inline void motion_interrupt(enum gpio_signal signal)
{
}

/*
 * Set EC_CROS_GPIO_INTERRUPTS to a space-separated list of GPIO_INT items.
 *
 * Each GPIO_INT requires three parameters:
 *   gpio_signal - The enum gpio_signal for the interrupt gpio
 *   interrupt_flags - The interrupt-related flags (e.g. GPIO_INT_EDGE_BOTH)
 *   handler - The platform/ec interrupt handler.
 *
 * Ensure that this files includes all necessary headers to declare all
 * referenced handler functions.
 *
 * For example, one could use the follow definition:
 * #define EC_CROS_GPIO_INTERRUPTS \
 *   GPIO_INT(NAMED_GPIO(h1_ec_pwr_btn_odl), GPIO_INT_EDGE_BOTH, button_print)
 */
#define EC_CROS_GPIO_INTERRUPTS						\
	GPIO_INT(GPIO_POWER_BUTTON_L,					\
		 GPIO_INT_EDGE_BOTH, power_button_interrupt)		\
	GPIO_INT(GPIO_LID_OPEN,						\
		 GPIO_INT_EDGE_BOTH, lid_interrupt)			\
	GPIO_INT(GPIO_TABLET_MODE_L,					\
		 GPIO_INT_EDGE_BOTH, gmr_tablet_switch_isr)		\
	GPIO_INT(GPIO_AP_EC_WARM_RST_REQ,				\
		 GPIO_INT_EDGE_RISING, chipset_reset_request_interrupt)	\
	GPIO_INT(GPIO_AP_IN_SLEEP_L,					\
		 GPIO_INT_EDGE_BOTH, power_signal_interrupt)		\
	GPIO_INT(GPIO_BASE_IMU_INT_L,					\
		 GPIO_INT_EDGE_FALLING, motion_interrupt)		\
	GPIO_INT(GPIO_LID_ACCEL_INT_L,					\
		 GPIO_INT_EDGE_FALLING, lis2dw12_interrupt)		\
	GPIO_INT(GPIO_VOLUME_DOWN_L,					\
		 GPIO_INT_EDGE_BOTH, button_interrupt)			\
	GPIO_INT(GPIO_VOLUME_UP_L,					\
		 GPIO_INT_EDGE_BOTH, button_interrupt)			\
	GPIO_INT(GPIO_AP_XHCI_INIT_DONE,				\
		 GPIO_INT_EDGE_BOTH, usb_a0_interrupt)			\
	GPIO_INT(GPIO_AC_PRESENT,					\
		 GPIO_INT_EDGE_BOTH, extpower_interrupt)		\
	GPIO_INT(GPIO_WP,						\
		 GPIO_INT_EDGE_BOTH, switch_interrupt)			\
	GPIO_INT(GPIO_SPI0_CS,						\
		 GPIO_INT_EDGE_FALLING, spi_event)			\
	GPIO_INT(GPIO_X_EC_GPIO2,					\
		 GPIO_INT_EDGE_BOTH, x_ec_interrupt)

#endif /* __ZEPHYR_GPIO_MAP_H */
```

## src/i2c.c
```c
/* Copyright 2021 The Chromium OS Authors. All rights reserved.
 * Use of this source code is governed by a BSD-style license that can be
 * found in the LICENSE file.
 */

#include "i2c/i2c.h"
#include "i2c.h"

/* Krabby board specific i2c implementation */

#ifdef CONFIG_PLATFORM_EC_I2C_PASSTHRU_RESTRICTED
int board_allow_i2c_passthru(int port)
{
	return (i2c_get_device_for_port(port) ==
		i2c_get_device_for_port(I2C_PORT_VIRTUAL_BATTERY));
}
#endif
```
